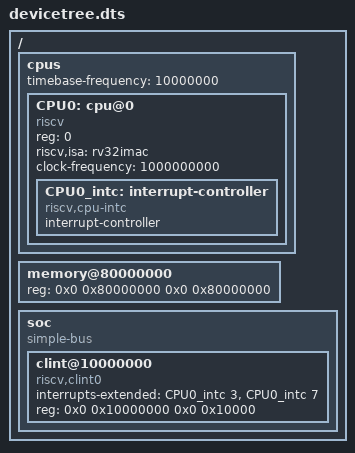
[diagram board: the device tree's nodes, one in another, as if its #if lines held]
/dts-v1/;

/ {
	#address-cells = <2>;
	#size-cells = <2>;
	cpus {
		#address-cells = <1>;
		#size-cells = <0>;
		timebase-frequency = <10000000>;
		CPU0: cpu@0 {
			device_type = "cpu";
			reg = <0>;
			status = "okay";
			compatible = "riscv";
#if __riscv_xlen == 32
			riscv,isa = "rv32imac";
#else
			riscv,isa = "rv64imafdc";
			mmu-type = "riscv,sv39";
#endif
			clock-frequency = <1000000000>;
			CPU0_intc: interrupt-controller {
				#interrupt-cells = <1>;
				interrupt-controller;
				compatible = "riscv,cpu-intc";
			};
		};
	};
	memory@80000000 {
		device_type = "memory";
		reg = <0x0 0x80000000 0x0 0x80000000>;
	};
	soc {
		#address-cells = <2>;
		#size-cells = <2>;
		compatible = "simple-bus";
		ranges;
		clint@10000000 {
			compatible = "riscv,clint0";
			interrupts-extended = <&CPU0_intc 3 &CPU0_intc 7 >;
			reg = <0x0 0x10000000 0x0 0x10000>;
		};
	};
};
